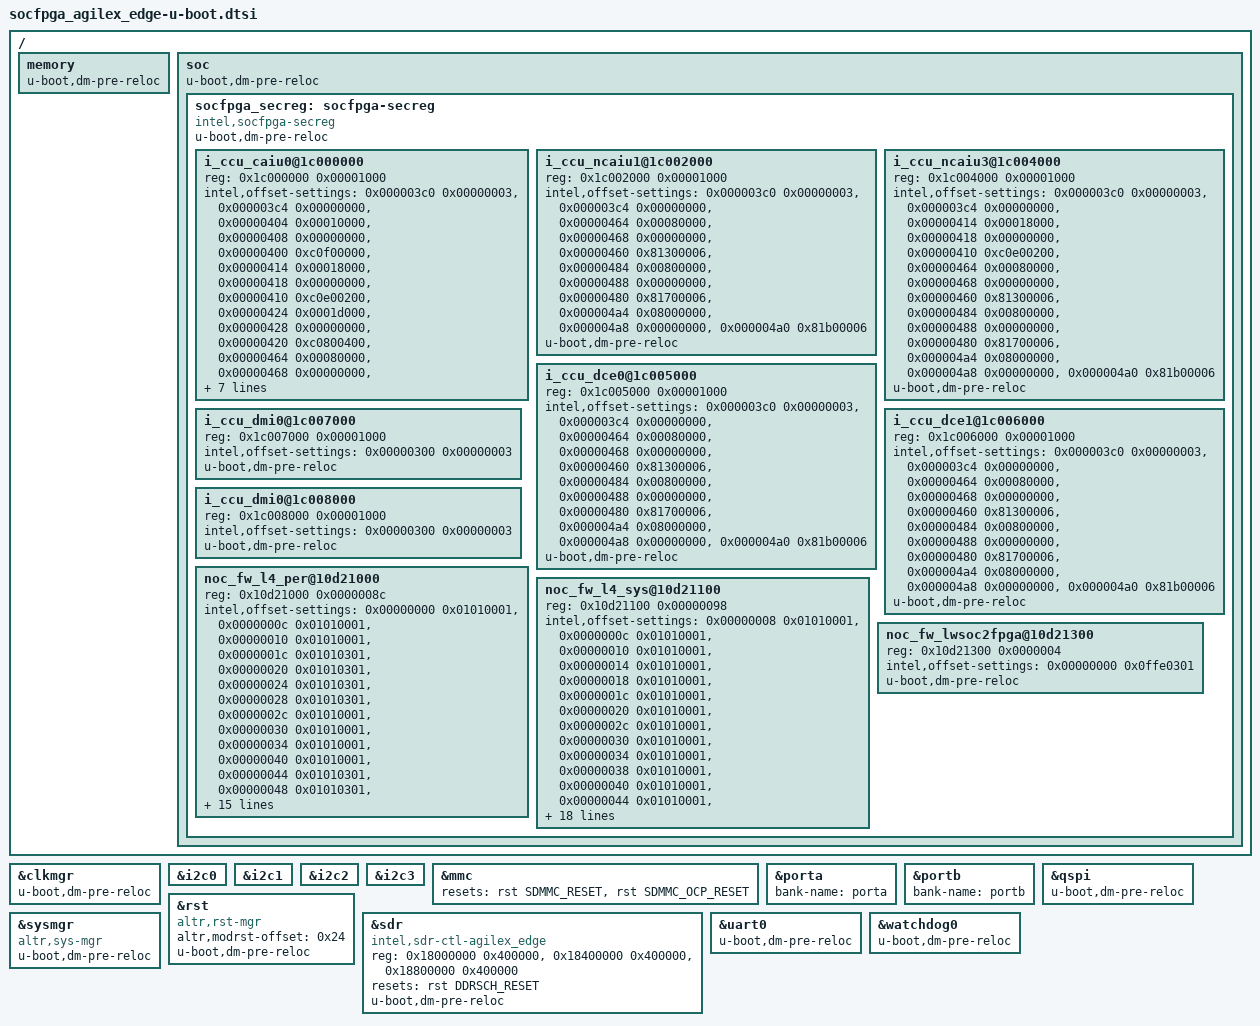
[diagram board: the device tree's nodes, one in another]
// SPDX-License-Identifier: GPL-2.0+
/*
 * U-Boot additions
 *
 * Copyright (C) 2019-2022 Intel Corporation <www.intel.com>
 */

#include "socfpga_soc64_fit-u-boot.dtsi"

/{
	memory {
		#address-cells = <2>;
		#size-cells = <2>;
		u-boot,dm-pre-reloc;
	};

	soc {
		u-boot,dm-pre-reloc;

		socfpga_secreg: socfpga-secreg {
			compatible = "intel,socfpga-secreg";
			#address-cells = <1>;
			#size-cells = <1>;
			u-boot,dm-pre-reloc;

			/* DSU */
			i_ccu_caiu0@1c000000 {
				reg = <0x1c000000 0x00001000>;
				intel,offset-settings =
					/* CAIUAMIGR */
					<0x000003c0 0x00000003>,
					/* CAIUMIFSR */
					<0x000003c4 0x00000000>,
					/* DII0_PSSPERIPHS */
					<0x00000404 0x00010000>,
					<0x00000408 0x00000000>,
					<0x00000400 0xc0f00000>,
					/* DII1_MPFEREGS */
					<0x00000414 0x00018000>,
					<0x00000418 0x00000000>,
					<0x00000410 0xc0e00200>,
					/* DII2_GICREGS */
					<0x00000424 0x0001d000>,
					<0x00000428 0x00000000>,
					<0x00000420 0xc0800400>,
					/* DMI_SDRAM_2G */
					<0x00000464 0x00080000>,
					<0x00000468 0x00000000>,
					<0x00000460 0x81300006>,
					/* DMI_SDRAM_30G */
					<0x00000484 0x00800000>,
					<0x00000488 0x00000000>,
					<0x00000480 0x81700006>,
					/* DMI_SDRAM_480G */
					<0x000004a4 0x08000000>,
					<0x000004a8 0x00000000>,
					<0x000004a0 0x81b00006>;
				u-boot,dm-pre-reloc;
			};

			/* GIC_M */
			i_ccu_ncaiu1@1c002000 {
				reg = <0x1c002000 0x00001000>;
				intel,offset-settings =
					/* NCAIU1AMIGR */
					<0x000003c0 0x00000003>,
					/* NCAIU1MIFSR */
					<0x000003c4 0x00000000>,
					/* DMI_SDRAM_2G */
					<0x00000464 0x00080000>,
					<0x00000468 0x00000000>,
					<0x00000460 0x81300006>,
					/* DMI_SDRAM_30G */
					<0x00000484 0x00800000>,
					<0x00000488 0x00000000>,
					<0x00000480 0x81700006>,
					/* DMI_SDRAM_480G */
					<0x000004a4 0x08000000>,
					<0x000004a8 0x00000000>,
					<0x000004a0 0x81b00006>;
				u-boot,dm-pre-reloc;
			};

			/* PSS NOC */
			i_ccu_ncaiu3@1c004000 {
				reg = <0x1c004000 0x00001000>;
				intel,offset-settings =
					/* NCAIU3AMIGR */
					<0x000003c0 0x00000003>,
					/* NCAIU3MIFSR */
					<0x000003c4 0x00000000>,
					/* DII1_MPFEREGS */
					<0x00000414 0x00018000>,
					<0x00000418 0x00000000>,
					<0x00000410 0xc0e00200>,
					/* DMI_SDRAM_2G */
					<0x00000464 0x00080000>,
					<0x00000468 0x00000000>,
					<0x00000460 0x81300006>,
					/* DMI_SDRAM_30G */
					<0x00000484 0x00800000>,
					<0x00000488 0x00000000>,
					<0x00000480 0x81700006>,
					/* DMI_SDRAM_480G */
					<0x000004a4 0x08000000>,
					<0x000004a8 0x00000000>,
					<0x000004a0 0x81b00006>;
				u-boot,dm-pre-reloc;
			};

			/* DCE0 */
			i_ccu_dce0@1c005000 {
				reg = <0x1c005000 0x00001000>;
				intel,offset-settings =
					/* DCEUAMIGR0 */
					<0x000003c0 0x00000003>,
					/* DCEUMIFSR0 */
					<0x000003c4 0x00000000>,
					/* DMI_SDRAM_2G */
					<0x00000464 0x00080000>,
					<0x00000468 0x00000000>,
					<0x00000460 0x81300006>,
					/* DMI_SDRAM_30G */
					<0x00000484 0x00800000>,
					<0x00000488 0x00000000>,
					<0x00000480 0x81700006>,
					/* DMI_SDRAM_480G */
					<0x000004a4 0x08000000>,
					<0x000004a8 0x00000000>,
					<0x000004a0 0x81b00006>;
				u-boot,dm-pre-reloc;
			};

			/* DCE1 */
			i_ccu_dce1@1c006000 {
				reg = <0x1c006000 0x00001000>;
				intel,offset-settings =
					/* DCEUAMIGR1 */
					<0x000003c0 0x00000003>,
					/* DCEUMIFSR1 */
					<0x000003c4 0x00000000>,
					/* DMI_SDRAM_2G */
					<0x00000464 0x00080000>,
					<0x00000468 0x00000000>,
					<0x00000460 0x81300006>,
					/* DMI_SDRAM_30G */
					<0x00000484 0x00800000>,
					<0x00000488 0x00000000>,
					<0x00000480 0x81700006>,
					/* DMI_SDRAM_480G */
					<0x000004a4 0x08000000>,
					<0x000004a8 0x00000000>,
					<0x000004a0 0x81b00006>;
				u-boot,dm-pre-reloc;
			};

			/* DMI0 */
			i_ccu_dmi0@1c007000 {
				reg = <0x1c007000 0x00001000>;
				intel,offset-settings =
					/* DCEUAMIGR1 */
					<0x00000300 0x00000003>;
				u-boot,dm-pre-reloc;
			};

			/* DMI1 */
			i_ccu_dmi0@1c008000 {
				reg = <0x1c008000 0x00001000>;
				intel,offset-settings =
					/* DCEUAMIGR1 */
					<0x00000300 0x00000003>;
				u-boot,dm-pre-reloc;
			};

			/* L4 peripherals firewall */
			noc_fw_l4_per@10d21000 {
				reg = <0x10d21000 0x0000008c>;
				intel,offset-settings =
					/* NAND */
					<0x00000000 0x01010001>,
					/* USB0 */
					<0x0000000c 0x01010001>,
					/* USB1 */
					<0x00000010 0x01010001>,
					/* SPI_MAIN0 */
					<0x0000001c 0x01010301>,
					/* SPI_MAIN1 */
					<0x00000020 0x01010301>,
					/* SPI_SECONDARY0 */
					<0x00000024 0x01010301>,
					/* SPI_SECONDARY1 */
					<0x00000028 0x01010301>,
					/* EMAC0 */
					<0x0000002c 0x01010001>,
					/* EMAC1 */
					<0x00000030 0x01010001>,
					/* EMAC2 */
					<0x00000034 0x01010001>,
					/* SDMMC */
					<0x00000040 0x01010001>,
					/* GPIO0 */
					<0x00000044 0x01010301>,
					/* GPIO1 */
					<0x00000048 0x01010301>,
					/* I2C0 */
					<0x00000050 0x01010301>,
					/* I2C1 */
					<0x00000054 0x01010301>,
					/* I2C2 */
					<0x00000058 0x01010301>,
					/* I2C3 */
					<0x0000005c 0x01010301>,
					/* I2C4 */
					<0x00000060 0x01010301>,
					/* SP_TIMER0 */
					<0x00000064 0x01010301>,
					/* SP_TIMER1 */
					<0x00000068 0x01010301>,
					/* UART0 */
					<0x0000006c 0x01010301>,
					/* UART1 */
					<0x00000070 0x01010301>,
					/* I3C0 */
					<0x00000074 0x01010301>,
					/* I3C1 */
					<0x00000078 0x01010301>,
					/* DMA0 */
					<0x0000007c 0x01010001>,
					/* DMA1 */
					<0x00000080 0x01010001>,
					/* COMBO_PHY */
					<0x00000084 0x01010001>,
					/* NAND_SDMA */
					<0x00000088 0x01010301>;
				u-boot,dm-pre-reloc;
			};

			/* L4 system firewall */
			noc_fw_l4_sys@10d21100 {
				reg = <0x10d21100 0x00000098>;
				intel,offset-settings =
					/* DMA_ECC */
					<0x00000008 0x01010001>,
					/* EMAC0RX_ECC */
					<0x0000000c 0x01010001>,
					/* EMAC0TX_ECC */
					<0x00000010 0x01010001>,
					/* EMAC1RX_ECC */
					<0x00000014 0x01010001>,
					/* EMAC1TX_ECC */
					<0x00000018 0x01010001>,
					/* EMAC2RX_ECC */
					<0x0000001c 0x01010001>,
					/* EMAC2TX_ECC */
					<0x00000020 0x01010001>,
					/* NAND_ECC */
					<0x0000002c 0x01010001>,
					/* NAND_READ_ECC */
					<0x00000030 0x01010001>,
					/* NAND_WRITE_ECC */
					<0x00000034 0x01010001>,
					/* OCRAM_ECC */
					<0x00000038 0x01010001>,
					/* SDMMC_ECC */
					<0x00000040 0x01010001>,
					/* USB0_ECC */
					<0x00000044 0x01010001>,
					/* USB1_CACHEECC */
					<0x00000048 0x01010001>,
					/* CLOCK_MANAGER */
					<0x0000004c 0x01010001>,
					/* IO_MANAGER */
					<0x00000054 0x01010001>,
					/* RESET_MANAGER */
					<0x00000058 0x01010001>,
					/* SYSTEM_MANAGER */
					<0x0000005c 0x01010001>,
					/* OSC0_TIMER */
					<0x00000060 0x01010301>,
					/* OSC1_TIMER0*/
					<0x00000064 0x01010301>,
					/* WATCHDOG0 */
					<0x00000068 0x01010301>,
					/* WATCHDOG1 */
					<0x0000006c 0x01010301>,
					/* WATCHDOG2 */
					<0x00000070 0x01010301>,
					/* WATCHDOG3 */
					<0x00000074 0x01010301>,
					/* DAP */
					<0x00000078 0x03010001>,
					/* WATCHDOG4 */
					<0x0000007c 0x01010301>,
					/* POWER_MANAGER */
					<0x00000080 0x01010001>,
					/* USB1_RXECC */
					<0x00000084 0x01010001>,
					/* USB1_TXECC */
					<0x00000088 0x01010001>,
					/* L4_NOC_PROBES */
					<0x00000090 0x01010001>,
					/* L4_NOC_QOS */
					<0x00000094 0x01010001>;
				u-boot,dm-pre-reloc;
			};

			/* Light weight SoC2FPGA */
			noc_fw_lwsoc2fpga@10d21300 {
				reg = <0x10d21300 0x0000004>;
				intel,offset-settings =
					/* LWSOC2FPGA_CSR */
					<0x00000000 0x0ffe0301>;
				u-boot,dm-pre-reloc;
			};
		};
	};
};

&clkmgr {
	u-boot,dm-pre-reloc;
};

&i2c0 {
	reset-names = "i2c";
};

&i2c1 {
	reset-names = "i2c";
};

&i2c2 {
	reset-names = "i2c";
};

&i2c3 {
	reset-names = "i2c";
};

&mmc {
	resets = <&rst SDMMC_RESET>, <&rst SDMMC_OCP_RESET>;
};

&porta {
	bank-name = "porta";
};

&portb {
	bank-name = "portb";
};

&qspi {
	u-boot,dm-pre-reloc;
};

&rst {
	compatible = "altr,rst-mgr";
	altr,modrst-offset = <0x24>;
	u-boot,dm-pre-reloc;
};

&sdr {
	compatible = "intel,sdr-ctl-agilex_edge";
	reg = <0x18000000 0x400000>,
	      <0x18400000 0x400000>,
	      <0x18800000 0x400000>;
	resets = <&rst DDRSCH_RESET>;
	u-boot,dm-pre-reloc;
};

&sysmgr {
	compatible = "altr,sys-mgr", "syscon";
	u-boot,dm-pre-reloc;
};

&uart0 {
	u-boot,dm-pre-reloc;
};

&watchdog0 {
	u-boot,dm-pre-reloc;
};
